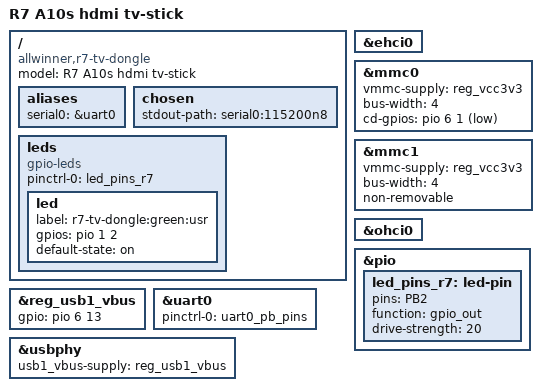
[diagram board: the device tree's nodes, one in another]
/dts-v1/;
#include "sun5i-a10s.dtsi"
#include "sunxi-common-regulators.dtsi"
#include <dt-bindings/gpio/gpio.h>
/ {
	model = "R7 A10s hdmi tv-stick";
	compatible = "allwinner,r7-tv-dongle", "allwinner,sun5i-a10s";
	aliases {
		serial0 = &uart0;
	};
	chosen {
		stdout-path = "serial0:115200n8";
	};
	leds {
		compatible = "gpio-leds";
		pinctrl-names = "default";
		pinctrl-0 = <&led_pins_r7>;
		led {
			label = "r7-tv-dongle:green:usr";
			gpios = <&pio 1 2 GPIO_ACTIVE_HIGH>;
			default-state = "on";
		};
	};
};
&ehci0 {
	status = "okay";
};
&mmc0 {
	vmmc-supply = <&reg_vcc3v3>;
	bus-width = <4>;
	cd-gpios = <&pio 6 1 GPIO_ACTIVE_LOW>;  
	status = "okay";
};
&mmc1 {
	vmmc-supply = <&reg_vcc3v3>;
	bus-width = <4>;
	non-removable;
	status = "okay";
};
&ohci0 {
	status = "okay";
};
&pio {
	led_pins_r7: led-pin {
		pins = "PB2";
		function = "gpio_out";
		drive-strength = <20>;
	};
};
&reg_usb1_vbus {
	gpio = <&pio 6 13 GPIO_ACTIVE_HIGH>;
	status = "okay";
};
&uart0 {
	pinctrl-names = "default";
	pinctrl-0 = <&uart0_pb_pins>;
	status = "okay";
};
&usbphy {
	usb1_vbus-supply = <&reg_usb1_vbus>;
	status = "okay";
};
